# STM32U083 register map
File version: 0.2
CPU: CM0+ r0p1, little endian, MPU, no FPU, 4 interrupt priority bits
Registers are 32-bit, read-write, reset 0x0 unless marked. A register's access mark holds for its fields unless they carry their own. Offsets are from the block's base; [hi:lo] are bit positions; {n}, {i} and the like mark numbered series; 'fields as' and 'values as' point back to an identical list.

## LPTIM1 — LPTIM1 address block description
Base 0x40007C00
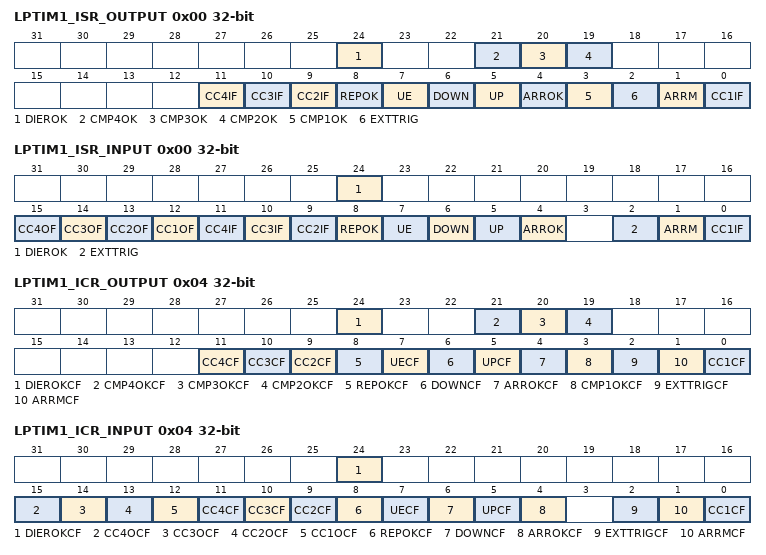
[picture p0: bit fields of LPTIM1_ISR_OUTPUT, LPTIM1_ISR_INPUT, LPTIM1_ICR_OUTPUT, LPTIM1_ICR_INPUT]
0x00 LPTIM1_ISR_OUTPUT ro — LPTIM1 interrupt and status register [alternate]
  [24] DIEROK — Interrupt enable register update OK DIEROK is set by hardware to inform application that the APB bus write operation to the LPTIM_DIER register has been successfully completed. DIEROK flag can be cleared by writing 1 to the DIEROKCF bit in the LPTIM_ICR register.
  [21] CMP4OK — Compare register 4 update OK CMP4OK is set by hardware to inform application that the APB bus write operation to the LPTIM_CCR4 register has been successfully completed. CMP4OK flag can be cleared by writing 1 to the CMP4OKCF bit in the LPTIM_ICR register. Note: If LPTIM does not implement at least 4 channels this bit is reserved. Refer to Section125.3.
  [20] CMP3OK — Compare register 3 update OK CMP3OK is set by hardware to inform application that the APB bus write operation to the LPTIM_CCR3 register has been successfully completed. CMP3OK flag can be cleared by writing 1 to the CMP3OKCF bit in the LPTIM_ICR register. Note: If LPTIM does not implement at least 3 channels this bit is reserved. Refer to Section125.3.
  [19] CMP2OK — Compare register 2 update OK CMP2OK is set by hardware to inform application that the APB bus write operation to the LPTIM_CCR2 register has been successfully completed. CMP2OK flag can be cleared by writing 1 to the CMP2OKCF bit in the LPTIM_ICR register. Note: If LPTIM does not implement at least 2 channels this bit is reserved. Refer to Section125.3.
  [11] CC4IF — Compare 4 interrupt flag If channel CC4 is configured as output: The CC4IF flag is set by hardware to inform application that LPTIM_CNT register value matches the compare register's value. CC4IF flag can be cleared by writing 1 to the CC4CF bit in the LPTIM_ICR register. Note: If LPTIM does not implement at least 4 channels this bit is reserved. Refer to Section125.3.
    0=No match; 1=The content of the counter LPTIM_CNT register value has matched the LPTIM_CCR4 register's value
  [10] CC3IF — Compare 3 interrupt flag If channel CC3 is configured as output: The CC3IF flag is set by hardware to inform application that LPTIM_CNT register value matches the compare register's value. CC3IF flag can be cleared by writing 1 to the CC3CF bit in the LPTIM_ICR register. Note: If LPTIM does not implement at least 3 channels this bit is reserved. Refer to Section125.3.
    0=No match; 1=The content of the counter LPTIM_CNT register value has matched the LPTIM_CCR3 register's value
  [9] CC2IF — Compare 2 interrupt flag If channel CC2 is configured as output: The CC2IF flag is set by hardware to inform application that LPTIM_CNT register value matches the compare register's value. CC2IF flag can be cleared by writing 1 to the CC2CF bit in the LPTIM_ICR register. Note: If LPTIM does not implement at least 2 channels this bit is reserved. Refer to Section125.3.
    0=No match; 1=The content of the counter LPTIM_CNT register value has matched the LPTIM_CCR2 register's value
  [8] REPOK — Repetition register update OK REPOK is set by hardware to inform application that the APB bus write operation to the LPTIM_RCR register has been successfully completed. REPOK flag can be cleared by writing 1 to the REPOKCF bit in the LPTIM_ICR register.
  [7] UE — LPTIM update event occurred UE is set by hardware to inform application that an update event was generated. The corresponding interrupt or DMA request is generated if enabled. UE flag can be cleared by writing 1 to the UECF bit in the LPTIM_ICR register. The UE flag is automatically cleared by hardware once the LPTIM_ARR register is written by any bus master like CPU or DMA.
  [6] DOWN — Counter direction change up to down In Encoder mode, DOWN bit is set by hardware to inform application that the counter direction has changed from up to down. DOWN flag can be cleared by writing 1 to the DOWNCF bit in the LPTIM_ICR register. Note: If the LPTIM does not support encoder mode feature, this bit is reserved. Refer to Section125.3.
  [5] UP — Counter direction change down to up In Encoder mode, UP bit is set by hardware to inform application that the counter direction has changed from down to up. UP flag can be cleared by writing 1 to the UPCF bit in the LPTIM_ICR register. Note: If the LPTIM does not support encoder mode feature, this bit is reserved. Refer to Section125.3.
  [4] ARROK — Autoreload register update OK ARROK is set by hardware to inform application that the APB bus write operation to the LPTIM_ARR register has been successfully completed. ARROK flag can be cleared by writing 1 to the ARROKCF bit in the LPTIM_ICR register.
  [3] CMP1OK — Compare register 1 update OK CMP1OK is set by hardware to inform application that the APB bus write operation to the LPTIM_CCR1 register has been successfully completed. CMP1OK flag can be cleared by writing 1 to the CMP1OKCF bit in the LPTIM_ICR register.
  [2] EXTTRIG — External trigger edge event EXTTRIG is set by hardware to inform application that a valid edge on the selected external trigger input has occurred. If the trigger is ignored because the timer has already started, then this flag is not set. EXTTRIG flag can be cleared by writing 1 to the EXTTRIGCF bit in the LPTIM_ICR register.
  [1] ARRM — Autoreload match ARRM is set by hardware to inform application that LPTIM_CNT registers value reached the LPTIM_ARR registers value. ARRM flag can be cleared by writing 1 to the ARRMCF bit in the LPTIM_ICR register.
  [0] CC1IF — Compare 1 interrupt flag If channel CC1 is configured as output: The CC1IF flag is set by hardware to inform application that LPTIM_CNT register value matches the compare register's value. CC1IF flag can be cleared by writing 1 to the CC1CF bit in the LPTIM_ICR register.
    0=No match; 1=The content of the counter LPTIM_CNT register value has matched the LPTIM_CCR1 register's value
0x00 LPTIM1_ISR_INPUT ro (alternate view of LPTIM1_ISR_OUTPUT) — LPTIM1 interrupt and status register [alternate]
  [24] DIEROK — Interrupt enable register update OK DIEROK is set by hardware to inform application that the APB bus write operation to the LPTIM_DIER register has been successfully completed. DIEROK flag can be cleared by writing 1 to the DIEROKCF bit in the LPTIM_ICR register.
  [15] CC4OF — Capture 4 over-capture flag This flag is set by hardware only when the corresponding channel is configured in input capture mode. It is cleared by software by writing 1 to the CC4OCF bit in the LPTIM_ICR register. Note: If LPTIM does not implement at least 4 channels this bit is reserved. Refer to Section125.3.
    0=No over-capture has been detected; 1=The counter value has been captured in LPTIM_CCR4 register while CC4IF flag was already set
  [14] CC3OF — Capture 3 over-capture flag This flag is set by hardware only when the corresponding channel is configured in input capture mode. It is cleared by software by writing 1 to the CC3OCF bit in the LPTIM_ICR register. Note: If LPTIM does not implement at least 3 channels this bit is reserved. Refer to Section125.3.
    0=No over-capture has been detected; 1=The counter value has been captured in LPTIM_CCR3 register while CC3IF flag was already set
  [13] CC2OF — Capture 2 over-capture flag This flag is set by hardware only when the corresponding channel is configured in input capture mode. It is cleared by software by writing 1 to the CC2OCF bit in the LPTIM_ICR register. Note: If LPTIM does not implement at least 2 channels this bit is reserved. Refer to Section125.3.
    0=No over-capture has been detected; 1=The counter value has been captured in LPTIM_CCR2 register while CC2IF flag was already set
  [12] CC1OF — Capture 1 over-capture flag This flag is set by hardware only when the corresponding channel is configured in input capture mode. It is cleared by software by writing 1 to the CC1OCF bit in the LPTIM_ICR register. Note: If LPTIM does not implement at least 1 channel this bit is reserved. Refer to Section125.3.
    0=No over-capture has been detected; 1=The counter value has been captured in LPTIM_CCR1 register while CC1IF flag was already set
  [11] CC4IF — Capture 4 interrupt flag If channel CC4 is configured as input: CC4IF is set by hardware to inform application that the current value of the counter is captured in LPTIM_CCR4 register. The corresponding interrupt or DMA request is generated if enabled. The CC4OF flag is set if the CC4IF flag was already high. Note: If LPTIM does not implement at least 4 channels this bit is reserved. Refer to Section125.3.
    0=No input capture occurred; 1=The counter value has been captured in the LPTIM_CCR4 register. (An edge has been detected on IC4 which matches the selected polarity). The CC4IF flag is automatically cleared by hardware once the captured value is read (CPU or DMA). The CC4IF flag can be cleared by writing 1 to the CC4CF bit in the LPTIM_ICR register.
  [10] CC3IF — Capture 3 interrupt flag If channel CC3 is configured as input: CC3IF is set by hardware to inform application that the current value of the counter is captured in LPTIM_CCR3 register. The corresponding interrupt or DMA request is generated if enabled. The CC3OF flag is set if the CC3IF flag was already high. Note: If LPTIM does not implement at least 3 channels this bit is reserved. Refer to Section125.3.
    0=No input capture occurred; 1=The counter value has been captured in the LPTIM_CCR3 register. (An edge has been detected on IC3 which matches the selected polarity). The CC3IF flag is automatically cleared by hardware once the captured value is read (CPU or DMA). The CC3IF flag can be cleared by writing 1 to the CC3CF bit in the LPTIM_ICR register.
  [9] CC2IF — Capture 2 interrupt flag If channel CC2 is configured as input: CC2IF is set by hardware to inform application that the current value of the counter is captured in LPTIM_CCR2 register. The corresponding interrupt or DMA request is generated if enabled. The CC2OF flag is set if the CC2IF flag was already high. Note: If LPTIM does not implement at least 2 channels this bit is reserved. Refer to Section125.3.
    0=No input capture occurred; 1=The counter value has been captured in the LPTIM_CCR2 register. (An edge has been detected on IC2 which matches the selected polarity). The CC2IF flag is automatically cleared by hardware once the captured value is read (CPU or DMA). The CC2IF flag can be cleared by writing 1 to the CC2CF bit in the LPTIM_ICR register.
  [8] REPOK — Repetition register update OK REPOK is set by hardware to inform application that the APB bus write operation to the LPTIM_RCR register has been successfully completed. REPOK flag can be cleared by writing 1 to the REPOKCF bit in the LPTIM_ICR register.
  [7] UE — LPTIM update event occurred UE is set by hardware to inform application that an update event was generated. UE flag can be cleared by writing 1 to the UECF bit in the LPTIM_ICR register.
  [6] DOWN — Counter direction change up to down In Encoder mode, DOWN bit is set by hardware to inform application that the counter direction has changed from up to down. DOWN flag can be cleared by writing 1 to the DOWNCF bit in the LPTIM_ICR register. Note: If the LPTIM does not support encoder mode feature, this bit is reserved. Refer to Section125.3.
  [5] UP — Counter direction change down to up In Encoder mode, UP bit is set by hardware to inform application that the counter direction has changed from down to up. UP flag can be cleared by writing 1 to the UPCF bit in the LPTIM_ICR register. Note: If the LPTIM does not support encoder mode feature, this bit is reserved. Refer to Section125.3.
  [4] ARROK — Autoreload register update OK ARROK is set by hardware to inform application that the APB bus write operation to the LPTIM_ARR register has been successfully completed. ARROK flag can be cleared by writing 1 to the ARROKCF bit in the LPTIM_ICR register.
  [2] EXTTRIG — External trigger edge event EXTTRIG is set by hardware to inform application that a valid edge on the selected external trigger input has occurred. If the trigger is ignored because the timer has already started, then this flag is not set. EXTTRIG flag can be cleared by writing 1 to the EXTTRIGCF bit in the LPTIM_ICR register.
  [1] ARRM — Autoreload match ARRM is set by hardware to inform application that LPTIM_CNT registers value reached the LPTIM_ARR registers value. ARRM flag can be cleared by writing 1 to the ARRMCF bit in the LPTIM_ICR register.
  [0] CC1IF — capture 1 interrupt flag If channel CC1 is configured as input: CC1IF is set by hardware to inform application that the current value of the counter is captured in LPTIM_CCR1 register. The corresponding interrupt or DMA request is generated if enabled. The CC1OF flag is set if the CC1IF flag was already high.
    0=No input capture occurred; 1=The counter value has been captured in the LPTIM_CCR1 register. (An edge has been detected on IC1 which matches the selected polarity). The CC1IF flag is automatically cleared by hardware once the captured value is read (CPU or DMA).CC1IF flag can be cleared by writing 1 to the CC1CF bit in the LPTIM_ICR register.
0x04 LPTIM1_ICR_OUTPUT wo — LPTIM1 interrupt clear register [alternate]
  [24] DIEROKCF — Interrupt enable register update OK clear flag Writing 1 to this bit clears the DIEROK flag in the LPTIM_ISR register.
  [21] CMP4OKCF — Compare register 4 update OK clear flag Writing 1 to this bit clears the CMP4OK flag in the LPTIM_ISR register. Note: If LPTIM does not implement at least 4 channels this bit is reserved. Refer to Section125.3.
  [20] CMP3OKCF — Compare register 3 update OK clear flag Writing 1 to this bit clears the CMP3OK flag in the LPTIM_ISR register. Note: If LPTIM does not implement at least 3 channels this bit is reserved. Refer to Section125.3.
  [19] CMP2OKCF — Compare register 2 update OK clear flag Writing 1 to this bit clears the CMP2OK flag in the LPTIM_ISR register. Note: If LPTIM does not implement at least 2 channels this bit is reserved. Refer to Section125.3.
  [11] CC4CF — Capture/compare 4 clear flag Writing 1 to this bit clears the CC4IF flag in the LPTIM_ISR register. Note: If LPTIM does not implement at least 4 channels this bit is reserved. Refer to Section125.3.
  [10] CC3CF — Capture/compare 3 clear flag Writing 1 to this bit clears the CC3IF flag in the LPTIM_ISR register. Note: If LPTIM does not implement at least 3 channels this bit is reserved. Refer to Section125.3.
  [9] CC2CF — Capture/compare 2 clear flag Writing 1 to this bit clears the CC2IF flag in the LPTIM_ISR register. Note: If LPTIM does not implement at least 2 channels this bit is reserved. Refer to Section125.3.
  [8] REPOKCF — Repetition register update OK clear flag Writing 1 to this bit clears the REPOK flag in the LPTIM_ISR register.
  [7] UECF — Update event clear flag Writing 1 to this bit clear the UE flag in the LPTIM_ISR register.
  [6] DOWNCF — Direction change to down clear flag Writing 1 to this bit clear the DOWN flag in the LPTIM_ISR register. Note: If the LPTIM does not support encoder mode feature, this bit is reserved. Refer to Section125.3.
  [5] UPCF — Direction change to UP clear flag Writing 1 to this bit clear the UP flag in the LPTIM_ISR register. Note: If the LPTIM does not support encoder mode feature, this bit is reserved. Refer to Section125.3.
  [4] ARROKCF — Autoreload register update OK clear flag Writing 1 to this bit clears the ARROK flag in the LPTIM_ISR register
  [3] CMP1OKCF — Compare register 1 update OK clear flag Writing 1 to this bit clears the CMP1OK flag in the LPTIM_ISR register.
  [2] EXTTRIGCF — External trigger valid edge clear flag Writing 1 to this bit clears the EXTTRIG flag in the LPTIM_ISR register
  [1] ARRMCF — Autoreload match clear flag Writing 1 to this bit clears the ARRM flag in the LPTIM_ISR register
  [0] CC1CF — Capture/compare 1 clear flag Writing 1 to this bit clears the CC1IF flag in the LPTIM_ISR register.
0x04 LPTIM1_ICR_INPUT wo (alternate view of LPTIM1_ICR_OUTPUT) — LPTIM1 interrupt clear register [alternate]
  [24] DIEROKCF — Interrupt enable register update OK clear flag Writing 1 to this bit clears the DIEROK flag in the LPTIM_ISR register.
  [15] CC4OCF — Capture/compare 4 over-capture clear flag Writing 1 to this bit clears the CC4OF flag in the LPTIM_ISR register. Note: If LPTIM does not implement at least 4 channels this bit is reserved. Refer to Section125.3.
  [14] CC3OCF — Capture/compare 3 over-capture clear flag Writing 1 to this bit clears the CC3OF flag in the LPTIM_ISR register. Note: If LPTIM does not implement at least 3 channels this bit is reserved. Refer to Section125.3.
  [13] CC2OCF — Capture/compare 2 over-capture clear flag Writing 1 to this bit clears the CC2OF flag in the LPTIM_ISR register. Note: If LPTIM does not implement at least 2 channels this bit is reserved. Refer to Section125.3.
  [12] CC1OCF — Capture/compare 1 over-capture clear flag Writing 1 to this bit clears the CC1OF flag in the LPTIM_ISR register. Note: If LPTIM does not implement at least 1 channel this bit is reserved. Refer to Section125.3.
  [11] CC4CF — Capture/compare 4 clear flag Writing 1 to this bit clears the CC4IF flag in the LPTIM_ISR register. Note: If LPTIM does not implement at least 4 channels this bit is reserved. Refer to Section125.3.
  [10] CC3CF — Capture/compare 3 clear flag Writing 1 to this bit clears the CC3IF flag in the LPTIM_ISR register. Note: If LPTIM does not implement at least 3 channels this bit is reserved. Refer to Section125.3.
  [9] CC2CF — Capture/compare 2 clear flag Writing 1 to this bit clears the CC2IF flag in the LPTIM_ISR register. Note: If LPTIM does not implement at least 2 channels this bit is reserved. Refer to Section125.3.
  [8] REPOKCF — Repetition register update OK clear flag Writing 1 to this bit clears the REPOK flag in the LPTIM_ISR register.
  [7] UECF — Update event clear flag Writing 1 to this bit clear the UE flag in the LPTIM_ISR register.
  [6] DOWNCF — Direction change to down clear flag Writing 1 to this bit clear the DOWN flag in the LPTIM_ISR register. Note: If the LPTIM does not support encoder mode feature, this bit is reserved. Refer to Section125.3.
  [5] UPCF — Direction change to UP clear flag Writing 1 to this bit clear the UP flag in the LPTIM_ISR register. Note: If the LPTIM does not support encoder mode feature, this bit is reserved. Refer to Section125.3.
  [4] ARROKCF — Autoreload register update OK clear flag Writing 1 to this bit clears the ARROK flag in the LPTIM_ISR register
  [2] EXTTRIGCF — External trigger valid edge clear flag Writing 1 to this bit clears the EXTTRIG flag in the LPTIM_ISR register
  [1] ARRMCF — Autoreload match clear flag Writing 1 to this bit clears the ARRM flag in the LPTIM_ISR register
  [0] CC1CF — Capture/compare 1 clear flag Writing 1 to this bit clears the CC1IF flag in the LPTIM_ISR register.
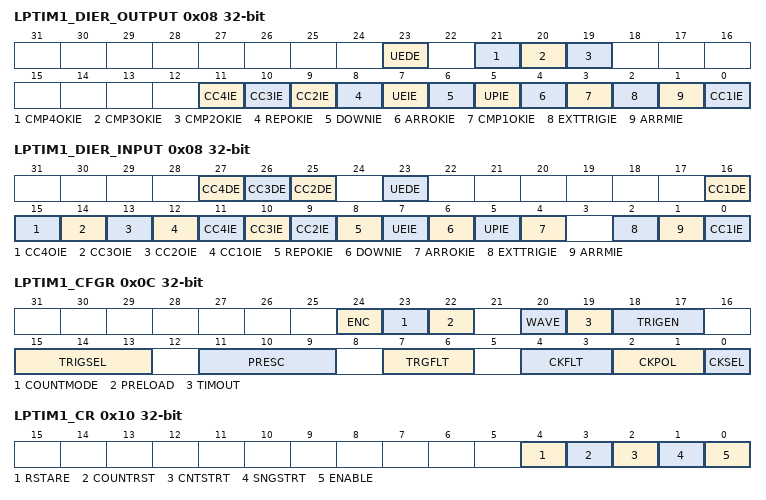
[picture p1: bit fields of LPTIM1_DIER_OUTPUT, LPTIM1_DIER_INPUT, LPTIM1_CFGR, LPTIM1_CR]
0x08 LPTIM1_DIER_OUTPUT — LPTIM1 interrupt enable register [alternate]
  [23] UEDE — Update event DMA request enable Note: If LPTIM does not implement at least 1 channel this bit is reserved. Refer to Section125.3.
    0=UE DMA request disabled. Writing '0' to the UEDE bit resets the associated ue_dma_req signal.; 1=UE DMA request enabled
  [21] CMP4OKIE — Compare register 4 update OK interrupt enable Note: If LPTIM does not implement at least 4 channels this bit is reserved. Refer to Section125.3.
    0=CMPOK register 4 interrupt disabled; 1=CMPOK register 4 interrupt enabled
  [20] CMP3OKIE — Compare register 3 update OK interrupt enable Note: If LPTIM does not implement at least 3 channels this bit is reserved. Refer to Section125.3.
    0=CMPOK register 3 interrupt disabled; 1=CMPOK register 3 interrupt enabled
  [19] CMP2OKIE — Compare register 2 update OK interrupt enable Note: If LPTIM does not implement at least 2 channels this bit is reserved. Refer to Section125.3.
    0=CMPOK register 2 interrupt disabled; 1=CMPOK register 2 interrupt enabled
  [11] CC4IE — Capture/compare 4 interrupt enable Note: If LPTIM does not implement at least 4 channels this bit is reserved. Refer to Section125.3.
    0=Capture/compare 4 interrupt disabled; 1=Capture/compare 4 interrupt enabled
  [10] CC3IE — Capture/compare 3 interrupt enable Note: If LPTIM does not implement at least 3 channels this bit is reserved. Refer to Section125.3.
    0=Capture/compare 3 interrupt disabled; 1=Capture/compare 3 interrupt enabled
  [9] CC2IE — Capture/compare 2 interrupt enable Note: If LPTIM does not implement at least 2 channels this bit is reserved. Refer to Section125.3.
    0=Capture/compare 2 interrupt disabled; 1=Capture/compare 2 interrupt enabled
  [8] REPOKIE — Repetition register update OK interrupt Enable
    0=Repetition register update OK interrupt disabled; 1=Repetition register update OK interrupt enabled
  [7] UEIE — Update event interrupt enable
    0=Update event interrupt disabled; 1=Update event interrupt enabled
  [6] DOWNIE — Direction change to down Interrupt Enable Note: If the LPTIM does not support encoder mode feature, this bit is reserved. Refer to Section125.3.
    0=DOWN interrupt disabled; 1=DOWN interrupt enabled
  [5] UPIE — Direction change to UP Interrupt Enable Note: If the LPTIM does not support encoder mode feature, this bit is reserved. Refer to Section125.3.
    0=UP interrupt disabled; 1=UP interrupt enabled
  [4] ARROKIE — Autoreload register update OK Interrupt Enable
    0=ARROK interrupt disabled; 1=ARROK interrupt enabled
  [3] CMP1OKIE — Compare register 1 update OK interrupt enable
    0=CMPOK register 1 interrupt disabled; 1=CMPOK register 1 interrupt enabled
  [2] EXTTRIGIE — External trigger valid edge Interrupt Enable
    0=EXTTRIG interrupt disabled; 1=EXTTRIG interrupt enabled
  [1] ARRMIE — Autoreload match Interrupt Enable
    0=ARRM interrupt disabled; 1=ARRM interrupt enabled
  [0] CC1IE — Capture/compare 1 interrupt enable
    0=Capture/compare 1 interrupt disabled; 1=Capture/compare 1 interrupt enabled
0x08 LPTIM1_DIER_INPUT (alternate view of LPTIM1_DIER_OUTPUT) — LPTIM1 interrupt enable register [alternate]
  [27] CC4DE — Capture/compare 4 DMA request enable Note: If LPTIM does not implement at least 4 channels this bit is reserved. Refer to Section125.3.
    0=CC4 DMA request disabled. Writing '0' to the CC4DE bit resets the associated ic4_dma_req signal.; 1=CC4 DMA request enabled
  [26] CC3DE — Capture/compare 3 DMA request enable Note: If LPTIM does not implement at least 3 channels this bit is reserved. Refer to Section125.3.
    0=CC3 DMA request disabled. Writing '0' to the CC3DE bit resets the associated ic3_dma_req signal.; 1=CC3 DMA request enabled
  [25] CC2DE — Capture/compare 2 DMA request enable Note: If LPTIM does not implement at least 2 channels this bit is reserved. Refer to Section125.3.
    0=CC2 DMA request disabled. Writing '0' to the CC2DE bit resets the associated ic2_dma_req signal.; 1=CC2 DMA request enabled
  [23] UEDE — Update event DMA request enable Note: If LPTIM does not implement at least 1 channel this bit is reserved. Refer to Section125.3.
    values as LPTIM1_DIER_OUTPUT.UEDE
  [16] CC1DE — Capture/compare 1 DMA request enable Note: If LPTIM does not implement at least 1 channel this bit is reserved. Refer to Section125.3.
    0=CC1 DMA request disabled. Writing '0' to the CC1DE bit resets the associated ic1_dma_req signal.; 1=CC1 DMA request enabled
  [15] CC4OIE — Capture/compare 4 over-capture interrupt enable Note: If LPTIM does not implement at least 4 channels this bit is reserved. Refer to Section125.3.
    0=CC4 over-capture interrupt disabled; 1=CC4 over-capture interrupt enabled
  [14] CC3OIE — Capture/compare 3 over-capture interrupt enable Note: If LPTIM does not implement at least 3 channels this bit is reserved. Refer to Section125.3.
    0=CC3 over-capture interrupt disabled; 1=CC3 over-capture interrupt enabled
  [13] CC2OIE — Capture/compare 2 over-capture interrupt enable Note: If LPTIM does not implement at least 2 channels this bit is reserved. Refer to Section125.3.
    0=CC2 over-capture interrupt disabled; 1=CC2 over-capture interrupt enabled
  [12] CC1OIE — Capture/compare 1 over-capture interrupt enable Note: If LPTIM does not implement at least 1 channel this bit is reserved. Refer to Section125.3.
    0=CC1 over-capture interrupt disabled; 1=CC1 over-capture interrupt enabled
  [11] CC4IE — Capture/compare 4 interrupt enable Note: If LPTIM does not implement at least 4 channels this bit is reserved. Refer to Section125.3.
    values as LPTIM1_DIER_OUTPUT.CC4IE
  [10] CC3IE — Capture/compare 3 interrupt enable Note: If LPTIM does not implement at least 3 channels this bit is reserved. Refer to Section125.3.
    values as LPTIM1_DIER_OUTPUT.CC3IE
  [9] CC2IE — Capture/compare 2 interrupt enable Note: If LPTIM does not implement at least 2 channels this bit is reserved. Refer to Section125.3.
    values as LPTIM1_DIER_OUTPUT.CC2IE
  [8] REPOKIE — Repetition register update OK interrupt Enable
    values as LPTIM1_DIER_OUTPUT.REPOKIE
  [7] UEIE — Update event interrupt enable
    values as LPTIM1_DIER_OUTPUT.UEIE
  [6] DOWNIE — Direction change to down Interrupt Enable Note: If the LPTIM does not support encoder mode feature, this bit is reserved. Refer to Section125.3.
    0=DOWN interrupt disabled; 1=DOWN interrupt enabled
  [5] UPIE — Direction change to UP Interrupt Enable Note: If the LPTIM does not support encoder mode feature, this bit is reserved. Refer to Section125.3.
    0=UP interrupt disabled; 1=UP interrupt enabled
  [4] ARROKIE — Autoreload register update OK Interrupt Enable
    0=ARROK interrupt disabled; 1=ARROK interrupt enabled
  [2] EXTTRIGIE — External trigger valid edge Interrupt Enable
    0=EXTTRIG interrupt disabled; 1=EXTTRIG interrupt enabled
  [1] ARRMIE — Autoreload match Interrupt Enable
    0=ARRM interrupt disabled; 1=ARRM interrupt enabled
  [0] CC1IE — Capture/compare 1 interrupt enable
    values as LPTIM1_DIER_OUTPUT.CC1IE
0x0C LPTIM1_CFGR — LPTIM configuration register
  [24] ENC — Encoder mode enable The ENC bit controls the Encoder mode Note: If the LPTIM does not support encoder mode feature, this bit is reserved. Refer to Section125.3.
    0=Encoder mode disabled; 1=Encoder mode enabled
  [23] COUNTMODE — counter mode enabled The COUNTMODE bit selects which clock source is used by the LPTIM to clock the counter:
    0=the counter is incremented following each internal clock pulse; 1=the counter is incremented following each valid clock pulse on the LPTIM external Input1
  [22] PRELOAD — Registers update mode The PRELOAD bit controls the LPTIM1_ARR, LPTIM1_RCR and the LPTIM1_CCRx registers update modality
    0=Registers are updated after each APB bus write access; 1=Registers are updated at the end of the current LPTIM period
  [20] WAVE — Waveform shape The WAVE bit controls the output shape
    0=Deactivate Set-once mode; 1=Activate the Set-once mode
  [19] TIMOUT — Timeout enable The TIMOUT bit controls the Timeout feature
    0=A trigger event arriving when the timer is already started is ignored; 1=A trigger event arriving when the timer is already started resets and restarts the LPTIM counter and the repetition counter
  [18:17] TRIGEN — Trigger enable and polarity The TRIGEN bits controls whether the LPTIM counter is started by an external trigger or not. If the external trigger option is selected, three configurations are possible for the trigger active edge:
    0=software trigger (counting start is initiated by software); 1=rising edge is the active edge; 2=falling edge is the active edge; 3=both edges are active edges
  [15:13] TRIGSEL — Trigger selector The TRIGSEL bits select the trigger source that serves as a trigger event for the LPTIM among the below 8 available sources: See Section125.4.3: LPTIM input and trigger mapping for details.
    {v}=LPTIM1_ext_trig{v} (v=0..7)
  [11:9] PRESC — Clock prescaler The PRESC bits configure the prescaler division factor. It can be one among the following division factors:
    0=/1; 1=/2; 2=/4; 3=/8; 4=/16; 5=/32; 6=/64; 7=/128
  [7:6] TRGFLT — Configurable digital filter for trigger The TRGFLT value sets the number of consecutive equal samples that are detected when a level change occurs on an internal trigger before it is considered as a valid level transition. An internal clock source must be present to use this feature
    0=any trigger active level change is considered as a valid trigger; 1=trigger active level change must be stable for at least 2 clock periods before it is considered as valid trigger; 2=trigger active level change must be stable for at least 4 clock periods before it is considered as valid trigger; 3=trigger active level change must be stable for at least 8 clock periods before it is considered as valid trigger
  [4:3] CKFLT — Configurable digital filter for external clock The CKFLT value sets the number of consecutive equal samples that are detected when a level change occurs on an external clock signal before it is considered as a valid level transition. An internal clock source must be present to use this feature
    0=any external clock signal level change is considered as a valid transition; 1=external clock signal level change must be stable for at least 2 clock periods before it is considered as valid transition; 2=external clock signal level change must be stable for at least 4 clock periods before it is considered as valid transition; 3=external clock signal level change must be stable for at least 8 clock periods before it is considered as valid transition
  [2:1] CKPOL — Clock Polarity When the LPTIM is clocked by an external clock source, CKPOL bits is used to configure the active edge or edges used by the counter: If the LPTIM is configured in Encoder mode (ENC bit is set), the encoder sub-mode 1 is active. If the LPTIM is configured in Encoder mode (ENC bit is set), the encoder sub-mode 2 is active. If the LPTIM is configured in Encoder mode (ENC bit is set), the encoder sub-mode 3 is active. Refer to Section125.4.15: Encoder mode for more details about Encoder mode sub-modes.
    0=the rising edge is the active edge used for counting; 1=the falling edge is the active edge used for counting; 2=both edges are active edges. When both external clock signal edges are considered active ones, the LPTIM must also be clocked by an internal clock source with a frequency equal to at least four times the external clock frequency.; 3=not allowed
  [0] CKSEL — Clock selector The CKSEL bit selects which clock source the LPTIM uses:
    0=LPTIM is clocked by internal clock source (APB clock or any of the embedded oscillators); 1=LPTIM is clocked by an external clock source through the LPTIM external Input1
0x10 LPTIM1_CR — LPTIM control register
  [4] RSTARE — Reset after read enable This bit is set and cleared by software. When RSTARE is set to '1', any read access to LPTIM1_CNT register asynchronously resets LPTIM1_CNT register content. This bit can be set only when the LPTIM is enabled.
  [3] COUNTRST — Counter reset This bit is set by software and cleared by hardware. When set to '1' this bit triggers a synchronous reset of the LPTIM1_CNT counter register. Due to the synchronous nature of this reset, it only takes place after a synchronization delay of 3 LPTimer core clock cycles (LPTimer core clock may be different from APB clock). This bit can be set only when the LPTIM is enabled. It is automatically reset by hardware. COUNTRST must never be set to '1' by software before it is already cleared to '0' by hardware. Software must consequently check that COUNTRST bit is already cleared to '0' before attempting to set it to '1'.
  [2] CNTSTRT — Timer start in Continuous mode This bit is set by software and cleared by hardware. In case of software start (TRIGEN[1:0] = 00), setting this bit starts the LPTIM in Continuous mode. If the software start is disabled (TRIGEN[1:0] different than 00), setting this bit starts the timer in Continuous mode as soon as an external trigger is detected. If this bit is set when a single pulse mode counting is ongoing, then the timer does not stop at the next match between the LPTIM1_ARR and LPTIM1_CNT registers and the LPTIM counter keeps counting in Continuous mode. This bit can be set only when the LPTIM is enabled. It is automatically reset by hardware.
  [1] SNGSTRT — LPTIM start in Single mode This bit is set by software and cleared by hardware. In case of software start (TRIGEN[1:0] = 00), setting this bit starts the LPTIM in single pulse mode. If the software start is disabled (TRIGEN[1:0] different than 00), setting this bit starts the LPTIM in single pulse mode as soon as an external trigger is detected. If this bit is set when the LPTIM is in continuous counting mode, then the LPTIM stops at the following match between LPTIM1_ARR and LPTIM1_CNT registers. This bit can only be set when the LPTIM is enabled. It is automatically reset by hardware.
  [0] ENABLE — LPTIM enable The ENABLE bit is set and cleared by software.
    0=LPTIM is disabled. Writing '0' to the ENABLE bit resets all the DMA request signals (input capture and update event DMA requests).; 1=LPTIM is enabled
0x14 LPTIM1_CCR1 — LPTIM compare register 1
  [15:0] CCR1 — Capture/compare 1 value If channel CC1 is configured as output: CCR1 is the value to be loaded in the capture/compare 1 register. Depending on the PRELOAD option, the CCR1 register is immediately updated if the PRELOAD bit is reset and updated at next LPTIM update event if PREOAD bit is reset. The capture/compare register 1 contains the value to be compared to the counter LPTIM1_CNT and signaled on OC1 output. If channel CC1 is configured as input: CCR1 becomes read-only, it contains the counter value transferred by the last input capture 1 event. The LPTIM1_CCR1 register is read-only and cannot be programmed.
0x18 LPTIM1_ARR reset 0x1 — LPTIM autoreload register
  [15:0] ARR — Auto reload value ARR is the autoreload value for the LPTIM. This value must be strictly greater than the CCRx[15:0] value.
0x1C LPTIM1_CNT ro — LPTIM counter register
  [15:0] CNT — Counter value When the LPTIM is running with an asynchronous clock, reading the LPTIM1_CNT register may return unreliable values. So in this case it is necessary to perform two consecutive read accesses and verify that the two returned values are identical.
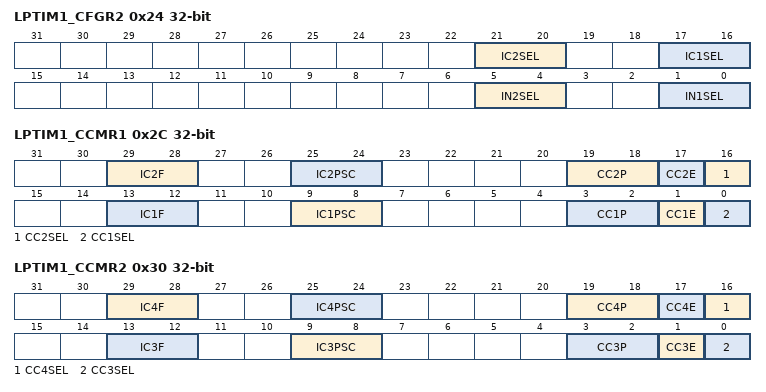
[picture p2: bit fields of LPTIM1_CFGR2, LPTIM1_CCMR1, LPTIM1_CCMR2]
0x24 LPTIM1_CFGR2 — LPTIM configuration register 2
  [21:20] IC2SEL — LPTIM input capture 2 selection The IC2SEL bits control the LPTIM Input capture 2 multiplexer, which connects LPTIM Input capture 2 to one of the available inputs. For connection details refer to Section125.4.3: LPTIM input and trigger mapping.
    {v}=LPTIM1_ic2_mux{v} (v=0..3)
  [17:16] IC1SEL — LPTIM input capture 1 selection The IC1SEL bits control the LPTIM Input capture 1 multiplexer, which connects LPTIM Input capture 1 to one of the available inputs. For connection details refer to Section125.4.3: LPTIM input and trigger mapping.
    {v}=LPTIM1_ic1_mux{v} (v=0..3)
  [5:4] IN2SEL — LPTIM input 2 selection The IN2SEL bits control the LPTIM input 2 multiplexer, which connects LPTIM input 2 to one of the available inputs. For connection details refer to Section125.4.3: LPTIM input and trigger mapping.
    {v}=LPTIM1_in2_mux{v} (v=0..3)
  [1:0] IN1SEL — LPTIM input 1 selection The IN1SEL bits control the LPTIM input 1 multiplexer, which connects LPTIM input 1 to one of the available inputs. For connection details refer to Section125.4.3: LPTIM input and trigger mapping.
    {v}=LPTIM1_in1_mux{v} (v=0..3)
0x28 LPTIM1_RCR — LPTIM repetition register
  [7:0] REP — Repetition register value REP is the repetition value for the LPTIM.
0x2C LPTIM1_CCMR1 — LPTIM capture/compare mode register 1
  [29:28] IC2F — Input capture 2 filter This bitfield defines the number of consecutive equal samples that are detected when a level change occurs on an external input capture signal before it is considered as a valid level transition. An internal clock source must be present to use this feature.
    0=any external input capture signal level change is considered as a valid transition; 1=external input capture signal level change must be stable for at least 2 clock periods before it is considered as valid transition; 2=external input capture signal level change must be stable for at least 4 clock periods before it is considered as valid transition; 3=external input capture signal level change must be stable for at least 8 clock periods before it is considered as valid transition
  [25:24] IC2PSC — Input capture 2 prescaler This bitfield defines the ratio of the prescaler acting on the CC2 input (IC2).
    0=no prescaler, capture is done each time an edge is detected on the capture input; 1=capture is done once every 2 events; 2=capture is done once every 4 events; 3=capture is done once every 8 events
  [19:18] CC2P — Capture/compare 2 output polarity. Only bit2 is used to set polarity when output mode is enabled, bit3 is don't care. This field is used to select the IC2 polarity for capture operations.
    0=B_0x0_CC2_AS_OUTPUT (OC2 active high); 1=B_0x1_CC2_AS_OUTPUT (OC2 active low); 0=B_0x0_CC2_AS_INPUT (rising edge, circuit is sensitive to IC2 rising edge); 1=B_0x1_CC2_AS_INPUT (falling edge, circuit is sensitive to IC2 falling edge); 2=B_0x2_CC2_AS_INPUT (reserved, do not use this configuration.); 3=B_0x3_CC2_AS_INPUT (both edges, circuit is sensitive to both IC2 rising and falling edges.)
  [17] CC2E — Capture/compare 2 output enable. This bit determines if a capture of the counter value can actually be done into the input capture/compare register 2 (LPTIM1_CCR2) or not.
    0=B_0x0_CC2_AS_OUTPUT (Off - OC2 is not active. Writing '0' to the CC2E bit resets the ue_dma_req signal only if all the other LPTIM channels are disabled.); 1=B_0x1_CC2_AS_OUTPUT (On - OC2 signal is output on the corresponding output pin); 0=B_0x0_CC2_AS_INPUT (Capture disabled. Writing '0' to the CC2E bit resets the associated ic2_dma_req signal.); 1=B_0x1_CC2_AS_INPUT (Capture enabled.)
  [16] CC2SEL — Capture/compare 2 selection This bitfield defines the direction of the channel, input (capture) or output mode.
    0=CC2 channel is configured in output PWM mode; 1=CC2 channel is configured in input capture mode
  [13:12] IC1F — Input capture 1 filter This bitfield defines the number of consecutive equal samples that are detected when a level change occurs on an external input capture signal before it is considered as a valid level transition. An internal clock source must be present to use this feature.
    values as IC2F
  [9:8] IC1PSC — Input capture 1 prescaler This bitfield defines the ratio of the prescaler acting on the CC1 input (IC1).
    values as IC2PSC
  [3:2] CC1P — Capture/compare 1 output polarity. Only bit2 is used to set polarity when output mode is enabled, bit3 is don't care. This field is used to select the IC1 polarity for capture operations.
    0=B_0x0_CC1_AS_OUTPUT (OC1 active high, the LPTIM output reflects the compare results between LPTIM1_ARR and LPTIM1_CCRx registers); 1=B_0x1_CC1_AS_OUTPUT (OC1 active low, the LPTIM output reflects the inverse of the compare results between LPTIM1_ARR and LPTIM1_CCRx registers); 0=B_0x0_CC1_AS_INPUT (rising edge, circuit is sensitive to IC1 rising edge); 1=B_0x1_CC1_AS_INPUT (falling edge, circuit is sensitive to IC1 falling edge); 2=B_0x2_CC1_AS_INPUT (reserved, do not use this configuration.); 3=B_0x3_CC1_AS_INPUT (both edges, circuit is sensitive to both IC1 rising and falling edges.)
  [1] CC1E — Capture/compare 1 output enable. This bit determines if a capture of the counter value can actually be done into the input capture/compare register 1 (LPTIM1_CCR1) or not.
    0=B_0x0_CC1_AS_OUTPUT (Off - OC1 is not active. Writing '0' to the CC1E bit resets the ue_dma_req signal only if all the other LPTIM channels are disabled.); 1=B_0x1_CC1_AS_OUTPUT (On - OC1 signal is output on the corresponding output pin); 0=B_0x0_CC1_AS_INPUT (Capture disabled. Writing '0' to the CC1E bit resets the associated ic1_dma_req signal.); 1=B_0x1_CC1_AS_INPUT (Capture enabled.)
  [0] CC1SEL — Capture/compare 1 selection This bitfield defines the direction of the channel input (capture) or output mode.
    0=CC1 channel is configured in output PWM mode; 1=CC1 channel is configured in input capture mode
0x30 LPTIM1_CCMR2 — LPTIM capture/compare mode register 2
  [29:28] IC4F — Input capture 4 filter This bitfield defines the number of consecutive equal samples that should be detected when a level change occurs on an external input capture signal before it is considered as a valid level transition. An internal clock source must be present to use this feature.
    values as LPTIM1_CCMR1.IC2F
  [25:24] IC4PSC — Input capture 4 prescaler This bitfield defines the ratio of the prescaler acting on the CC4 input (IC4).
    values as LPTIM1_CCMR1.IC2PSC
  [19:18] CC4P — Capture/compare 4 output polarity. Condition: CC4 as output: Only bit2 is used to set polarity when output mode is enabled, bit3 is don't care. Condition: CC4 as input: This field is used to select the IC4 polarity for capture operations.
    0=rising edge, circuit is sensitive to IC4 rising edge; 1=falling edge, circuit is sensitive to IC4 falling edge; 2=reserved, do not use this configuration; 3=both edges, circuit is sensitive to both IC4 rising and falling edges
  [17] CC4E — Capture/compare 4 output enable. Condition: CC4 as output: Condition: CC4 as input: This bit determines if a capture of the counter value can actually be done into the input capture/compare register 4 (LPTIM1_CCR4) or not.
    0=Capture disabled. Writing '0' to the CC4E bit resets the associated ic4_dma_req signal.; 1=Capture enabled
  [16] CC4SEL — Capture/compare 4 selection This bitfield defines the direction of the channel, input (capture) or output mode.
    0=CC4 channel is configured in output PWM mode; 1=CC4 channel is configured in input capture mode
  [13:12] IC3F — Input capture 3 filter This bitfield defines the number of consecutive equal samples that should be detected when a level change occurs on an external input capture signal before it is considered as a valid level transition. An internal clock source must be present to use this feature.
    values as LPTIM1_CCMR1.IC2F
  [9:8] IC3PSC — Input capture 3 prescaler This bitfield defines the ratio of the prescaler acting on the CC3 input (IC3).
    values as LPTIM1_CCMR1.IC2PSC
  [3:2] CC3P — Capture/compare 3 output polarity. Condition: CC3 as output: Only bit2 is used to set polarity when output mode is enabled, bit3 is don't care. Condition: CC3 as input: This field is used to select the IC3 polarity for capture operations.
    0=rising edge, circuit is sensitive to IC3 rising edge; 1=falling edge, circuit is sensitive to IC3 falling edge; 2=reserved, do not use this configuration; 3=both edges, circuit is sensitive to both IC3 rising and falling edges
  [1] CC3E — Capture/compare 3 output enable. Condition: CC3 as output: Condition: CC3 as input: This bit determines if a capture of the counter value can actually be done into the input capture/compare register 3 (LPTIM1_CCR3) or not.
    0=Capture disabled. Writing '0' to the CC3E bit resets the associated ic3_dma_req signal.; 1=Capture enabled
  [0] CC3SEL — Capture/compare 3 selection This bitfield defines the direction of the channel input (capture) or output mode.
    0=CC3 channel is configured in output PWM mode; 1=CC3 channel is configured in input capture mode
{0x2C+4i} LPTIM1_CCR{i} (i=2..4) — LPTIM compare register {i}
  [15:0] CCR{i} — Capture/compare {i} value If channel CC{i} is configured as output: CCR{i} is the value to be loaded in the capture/compare {i} register. Depending on the PRELOAD option, the CCR{i} register is immediately updated if the PRELOAD bit is reset and updated at next LPTIM update event if PREOAD bit is reset. The capture/compare register {i} contains the value to be compared to the counter LPTIM1_CNT and signaled on OC{i} output. If channel CC{i} is configured as input: CCR{i} becomes read-only, it contains the counter value transferred by the last input capture {i} event. The LPTIM1_CCR{i} register is read-only and cannot be programmed.

## LPTIM2 — LPTIM2 address block description
Base 0x40009400
Registers as LPTIM1 (with LPTIM1 read as LPTIM2).

## LPTIM3 — LPTIM3 address block description
Base 0x40009000
Registers as LPTIM1 (with LPTIM1 read as LPTIM3).
